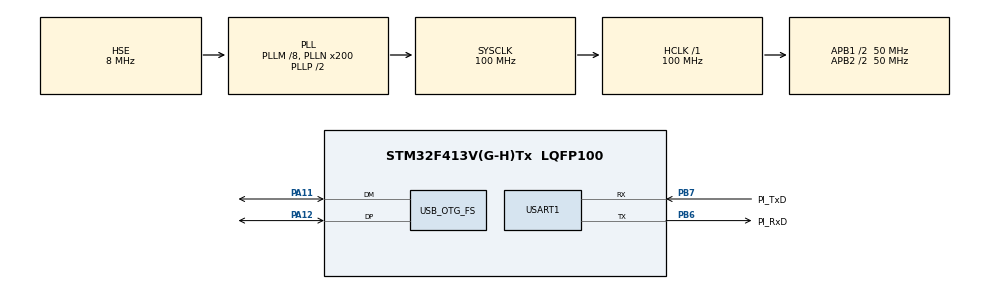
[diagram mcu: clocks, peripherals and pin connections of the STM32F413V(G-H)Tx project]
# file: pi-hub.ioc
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Dma.Request0=USART1_RX
Dma.USART1_RX.0.Direction=DMA_PERIPH_TO_MEMORY
Dma.USART1_RX.0.FIFOMode=DMA_FIFOMODE_ENABLE
Dma.USART1_RX.0.FIFOThreshold=DMA_FIFO_THRESHOLD_3QUARTERSFULL
Dma.USART1_RX.0.Instance=DMA2_Stream2
Dma.USART1_RX.0.MemBurst=DMA_MBURST_SINGLE
Dma.USART1_RX.0.MemDataAlignment=DMA_MDATAALIGN_BYTE
Dma.USART1_RX.0.MemInc=DMA_MINC_ENABLE
Dma.USART1_RX.0.Mode=DMA_NORMAL
Dma.USART1_RX.0.PeriphBurst=DMA_PBURST_SINGLE
Dma.USART1_RX.0.PeriphDataAlignment=DMA_PDATAALIGN_BYTE
Dma.USART1_RX.0.PeriphInc=DMA_PINC_DISABLE
Dma.USART1_RX.0.Priority=DMA_PRIORITY_LOW
Mcu.Family=STM32F4
Mcu.Name=STM32F413V(G-H)Tx
Mcu.Package=LQFP100
NVIC.DMA2_Stream2_IRQn=true\:0\:0\:false\:false\:true\:false\:true\:true
NVIC.OTG_FS_IRQn=true\:0\:0\:false\:false\:true\:false\:true\:true
NVIC.PriorityGroup=NVIC_PRIORITYGROUP_4
NVIC.USART1_IRQn=true\:0\:0\:false\:false\:true\:true\:true\:true
PA11.Mode=Device_Only
PA11.Signal=USB_OTG_FS_DM
PA12.Mode=Device_Only
PA12.Signal=USB_OTG_FS_DP
PA13.Mode=Serial_Wire
PA13.Signal=SYS_JTMS-SWDIO
PA14.Mode=Serial_Wire
PA14.Signal=SYS_JTCK-SWCLK
PB6.GPIO_Label=PI_RxD
PB6.GPIO_ModeDefaultPP=GPIO_MODE_AF_OD
PB6.GPIO_PuPd=GPIO_PULLUP
PB6.GPIO_Speed=GPIO_SPEED_FREQ_MEDIUM
PB6.Mode=Asynchronous
PB6.Signal=USART1_TX
PB7.GPIO_Label=PI_TxD
PB7.GPIO_PuPd=GPIO_PULLUP
PB7.GPIO_Speed=GPIO_SPEED_FREQ_MEDIUM
PB7.Mode=Asynchronous
PB7.Signal=USART1_RX
PC14-OSC32_IN.Mode=LSE-External-Oscillator
PC14-OSC32_IN.Signal=RCC_OSC32_IN
PC15-OSC32_OUT.Mode=LSE-External-Oscillator
PC15-OSC32_OUT.Signal=RCC_OSC32_OUT
PH0\ -\ OSC_IN.Mode=HSE-External-Oscillator
PH0\ -\ OSC_IN.Signal=RCC_OSC_IN
PH1\ -\ OSC_OUT.Mode=HSE-External-Oscillator
PH1\ -\ OSC_OUT.Signal=RCC_OSC_OUT
ProjectManager.HeapSize=0x200
ProjectManager.StackSize=0x400
ProjectManager.TargetToolchain=STM32CubeIDE
RCC.AHBFreq_Value=100000000
RCC.APB1CLKDivider=RCC_HCLK_DIV2
RCC.APB1Freq_Value=50000000
RCC.APB1TimFreq_Value=100000000
RCC.APB2CLKDivider=RCC_HCLK_DIV2
RCC.APB2Freq_Value=50000000
RCC.APB2TimFreq_Value=100000000
RCC.CortexFreq_Value=100000000
RCC.HCLKFreq_Value=100000000
RCC.HSE_VALUE=8000000
RCC.LSE_Timout=5000
RCC.PLLI2SM=8
RCC.PLLI2SQ=4
RCC.PLLM=8
RCC.PLLN=200
RCC.PLLSourceVirtual=RCC_PLLSOURCE_HSE
RCC.RCC_RTC_Clock_SourceVirtual=RCC_RTCCLKSOURCE_LSE
RCC.RCC_TIM_PRescaler_Selection=RCC_TIMPRES_DESACTIVATED
RCC.SYSCLKFreq_VALUE=100000000
RCC.SYSCLKSource=RCC_SYSCLKSOURCE_PLLCLK
RCC.USBCLockSelection=RCC_CLK48CLKSOURCE_PLLI2SQ
RCC.USBFreq_Value=48000000
RCC.VCOOutputFreq_Value=200000000
RTC.SynchPrediv=255
USART1.VirtualMode=VM_ASYNC
USB_DEVICE.APP_RX_DATA_SIZE=64
USB_DEVICE.APP_TX_DATA_SIZE=64
USB_DEVICE.CLASS_NAME_FS=CDC
USB_DEVICE.USBD_MAX_NUM_CONFIGURATION=1
USB_DEVICE.USBD_MAX_NUM_INTERFACES=4
USB_DEVICE.USBD_SELF_POWERED=0
USB_DEVICE.VirtualMode=Cdc
USB_DEVICE.VirtualModeFS=Cdc_FS
USB_OTG_FS.VirtualMode=Device_Only
VP_RTC_VS_RTC_Activate.Mode=RTC_Enabled
VP_USB_DEVICE_VS_USB_DEVICE_CDC_FS.Mode=CDC_FS
board=custom

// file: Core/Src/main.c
/* USER CODE BEGIN Header */
/**
  ******************************************************************************
  * @file           : main.c
  * @brief          : Main program body
  ******************************************************************************
  * @attention
  *
  * Copyright (c) 2022 STMicroelectronics.
  * All rights reserved.
  *
  * This software is licensed under terms that can be found in the LICENSE file
  * in the root directory of this software component.
  * If no LICENSE file comes with this software, it is provided AS-IS.
  *
  ******************************************************************************
  */
/* USER CODE END Header */
#include "main.h"
#include "usb_device.h"
#include "usbd_cdc.h"
#include "usbd_cdc_if.h"
#include "ring_buf.h"

RTC_HandleTypeDef hrtc;

UART_HandleTypeDef huart1;
DMA_HandleTypeDef hdma_usart1_rx;

void SystemClock_Config(void);
static void MX_GPIO_Init(void);
static void MX_DMA_Init(void);
static void MX_RTC_Init(void);
static void MX_USART1_UART_Init(void);

/* USER CODE BEGIN 0 */

t_ring cdc_rx_ring[CDC_NUM];
uint8_t cdc_tx_buff[CDC_NUM][RING_BUF_SIZE];

void uart_tick(void) {
  for (int i=0;i<CDC_NUM;i++){
    // transmit data
    if (CDC_Transmit_Ready(i) == USBD_OK){
      uint16_t data_len = ring_get_data(&cdc_rx_ring[i], cdc_tx_buff[i], RING_BUF_SIZE);
      if (data_len)
        CDC_Transmit_FS(i,cdc_tx_buff[i], data_len);
    }
    CDC_Receive_Handler(i);
  }
}

/* USER CODE END 0 */

int main(void)
{

  /* MCU Configuration--------------------------------------------------------*/

  /* Reset of all peripherals, Initializes the Flash interface and the Systick. */
  HAL_Init();

  /* Configure the system clock */
  SystemClock_Config();

  /* Initialize all configured peripherals */
  MX_GPIO_Init();
  MX_DMA_Init();
  MX_RTC_Init();
  MX_USART1_UART_Init();
  MX_USB_DEVICE_Init();

  /* Infinite loop */
  while (1)
  {

    /* USER CODE BEGIN 3 */
	uart_tick();
  }
  /* USER CODE END 3 */
}

void SystemClock_Config(void)
{
  RCC_OscInitTypeDef RCC_OscInitStruct = {0};
  RCC_ClkInitTypeDef RCC_ClkInitStruct = {0};

  /** Configure the main internal regulator output voltage
  */
  __HAL_RCC_PWR_CLK_ENABLE();
  __HAL_PWR_VOLTAGESCALING_CONFIG(PWR_REGULATOR_VOLTAGE_SCALE1);

  /** Initializes the RCC Oscillators according to the specified parameters
  * in the RCC_OscInitTypeDef structure.
  */
  RCC_OscInitStruct.OscillatorType = RCC_OSCILLATORTYPE_HSE|RCC_OSCILLATORTYPE_LSE;
  RCC_OscInitStruct.HSEState = RCC_HSE_ON;
  RCC_OscInitStruct.LSEState = RCC_LSE_ON;
  RCC_OscInitStruct.PLL.PLLState = RCC_PLL_ON;
  RCC_OscInitStruct.PLL.PLLSource = RCC_PLLSOURCE_HSE;
  RCC_OscInitStruct.PLL.PLLM = 8;
  RCC_OscInitStruct.PLL.PLLN = 200;
  RCC_OscInitStruct.PLL.PLLP = RCC_PLLP_DIV2;
  RCC_OscInitStruct.PLL.PLLQ = 2;
  RCC_OscInitStruct.PLL.PLLR = 2;
  if (HAL_RCC_OscConfig(&RCC_OscInitStruct) != HAL_OK)
  {
    Error_Handler();
  }

  /** Initializes the CPU, AHB and APB buses clocks
  */
  RCC_ClkInitStruct.ClockType = RCC_CLOCKTYPE_HCLK|RCC_CLOCKTYPE_SYSCLK
                              |RCC_CLOCKTYPE_PCLK1|RCC_CLOCKTYPE_PCLK2;
  RCC_ClkInitStruct.SYSCLKSource = RCC_SYSCLKSOURCE_PLLCLK;
  RCC_ClkInitStruct.AHBCLKDivider = RCC_SYSCLK_DIV1;
  RCC_ClkInitStruct.APB1CLKDivider = RCC_HCLK_DIV2;
  RCC_ClkInitStruct.APB2CLKDivider = RCC_HCLK_DIV2;

  if (HAL_RCC_ClockConfig(&RCC_ClkInitStruct, FLASH_LATENCY_3) != HAL_OK)
  {
    Error_Handler();
  }
}

static void MX_RTC_Init(void)
{

  /** Initialize RTC Only
  */
  hrtc.Instance = RTC;
  hrtc.Init.HourFormat = RTC_HOURFORMAT_24;
  hrtc.Init.AsynchPrediv = 127;
  hrtc.Init.SynchPrediv = 255;
  hrtc.Init.OutPut = RTC_OUTPUT_DISABLE;
  hrtc.Init.OutPutPolarity = RTC_OUTPUT_POLARITY_HIGH;
  hrtc.Init.OutPutType = RTC_OUTPUT_TYPE_OPENDRAIN;
  if (HAL_RTC_Init(&hrtc) != HAL_OK)
  {
    Error_Handler();
  }

}

static void MX_USART1_UART_Init(void)
{

  huart1.Instance = USART1;
  huart1.Init.BaudRate = 115200;
  huart1.Init.WordLength = UART_WORDLENGTH_8B;
  huart1.Init.StopBits = UART_STOPBITS_1;
  huart1.Init.Parity = UART_PARITY_NONE;
  huart1.Init.Mode = UART_MODE_TX_RX;
  huart1.Init.HwFlowCtl = UART_HWCONTROL_NONE;
  huart1.Init.OverSampling = UART_OVERSAMPLING_16;
  if (HAL_UART_Init(&huart1) != HAL_OK)
  {
    Error_Handler();
  }

}

static void MX_DMA_Init(void)
{

  /* DMA controller clock enable */
  __HAL_RCC_DMA2_CLK_ENABLE();

  /* DMA interrupt init */
  /* DMA2_Stream2_IRQn interrupt configuration */
  HAL_NVIC_SetPriority(DMA2_Stream2_IRQn, 0, 0);
  HAL_NVIC_EnableIRQ(DMA2_Stream2_IRQn);

}

static void MX_GPIO_Init(void)
{

  /* GPIO Ports Clock Enable */
  __HAL_RCC_GPIOC_CLK_ENABLE();
  __HAL_RCC_GPIOH_CLK_ENABLE();
  __HAL_RCC_GPIOA_CLK_ENABLE();
  __HAL_RCC_GPIOB_CLK_ENABLE();

}

void Error_Handler(void)
{
  __disable_irq();
  while (1)
  {
  }
}
